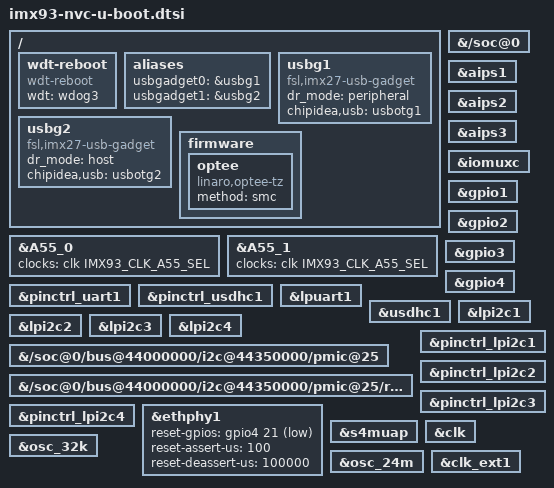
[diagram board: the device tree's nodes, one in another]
// SPDX-License-Identifier: GPL-2.0+
/*
 * Copyright 2025 Ezurio
 */

#include "imx93-u-boot.dtsi"

/ {
	wdt-reboot {
		compatible = "wdt-reboot";
		wdt = <&wdog3>;
		bootph-pre-ram;
		bootph-some-ram;
	};

	aliases {
		usbgadget0 = &usbg1;
		usbgadget1 = &usbg2;
	};

	usbg1: usbg1 {
		compatible = "fsl,imx27-usb-gadget";
		dr_mode = "peripheral";
		chipidea,usb = <&usbotg1>;
		status = "okay";
	};

	usbg2: usbg2 {
		compatible = "fsl,imx27-usb-gadget";
		dr_mode = "host";
		chipidea,usb = <&usbotg2>;
		status = "okay";
	};

	firmware {
		optee {
			compatible = "linaro,optee-tz";
			method = "smc";
		};
	};
};

&A55_0 {
	clocks = <&clk IMX93_CLK_A55_SEL>;
};

&A55_1 {
	clocks = <&clk IMX93_CLK_A55_SEL>;
};

&{/soc@0} {
	bootph-all;
	bootph-pre-ram;
};

&aips1 {
	bootph-pre-ram;
	bootph-all;
};

&aips2 {
	bootph-pre-ram;
	bootph-some-ram;
};

&aips3 {
	bootph-pre-ram;
	bootph-some-ram;
};

&iomuxc {
	bootph-pre-ram;
	bootph-some-ram;
};

&pinctrl_uart1 {
	bootph-pre-ram;
	bootph-some-ram;
};

&pinctrl_usdhc1 {
	bootph-pre-ram;
};

&gpio1 {
	bootph-pre-ram;
	bootph-some-ram;
};

&gpio2 {
	bootph-pre-ram;
	bootph-some-ram;
};

&gpio3 {
	bootph-pre-ram;
	bootph-some-ram;
};

&gpio4 {
	bootph-pre-ram;
	bootph-some-ram;
};

&lpuart1 {
	bootph-pre-ram;
	bootph-some-ram;
};

&usdhc1 {
	bootph-pre-ram;
};

&lpi2c1 {
	bootph-pre-ram;
};

&lpi2c2 {
	bootph-pre-ram;
};

&lpi2c3 {
	bootph-pre-ram;
};

&lpi2c4 {
	bootph-pre-ram;
};

&{/soc@0/bus@44000000/i2c@44350000/pmic@25} {
	bootph-pre-ram;
};

&{/soc@0/bus@44000000/i2c@44350000/pmic@25/regulators} {
	bootph-pre-ram;
};

&pinctrl_lpi2c1 {
	bootph-pre-ram;
};

&pinctrl_lpi2c2 {
	bootph-pre-ram;
};

&pinctrl_lpi2c3 {
	bootph-pre-ram;
};

&pinctrl_lpi2c4 {
	bootph-pre-ram;
};

&ethphy1 {
	reset-gpios = <&gpio4 21 GPIO_ACTIVE_LOW>;
	reset-assert-us = <100>;
	reset-deassert-us = <100000>;
};

&s4muap {
	bootph-pre-ram;
	bootph-some-ram;
	status = "okay";
};

&clk {
	bootph-all;
	bootph-pre-ram;
	/delete-property/ assigned-clocks;
	/delete-property/ assigned-clock-rates;
	/delete-property/ assigned-clock-parents;
};

&osc_32k {
	bootph-all;
	bootph-pre-ram;
};

&osc_24m {
	bootph-all;
	bootph-pre-ram;
};

&clk_ext1 {
	bootph-all;
	bootph-pre-ram;
};
